# nrf7140_wificore register map
Vendor: Nordic Semiconductor; Series: nRF71; File version: 1
Registers are 32-bit, read-write, reset 0x0 unless marked. A register's access mark holds for its fields unless they carry their own. Offsets are from the block's base; [hi:lo] are bit positions; lines under a group give offsets from that group; {n}, {i} and the like mark numbered series; 'fields as' and 'values as' point back to an identical list.

## GLOBAL_MEMCONF310 — Memory configuration
Base 0x49011000
Same registers: MEMCONF 0x48013000
{0x500+0x10*i} POWER[{i}] (i=0..1) group — Unspecified
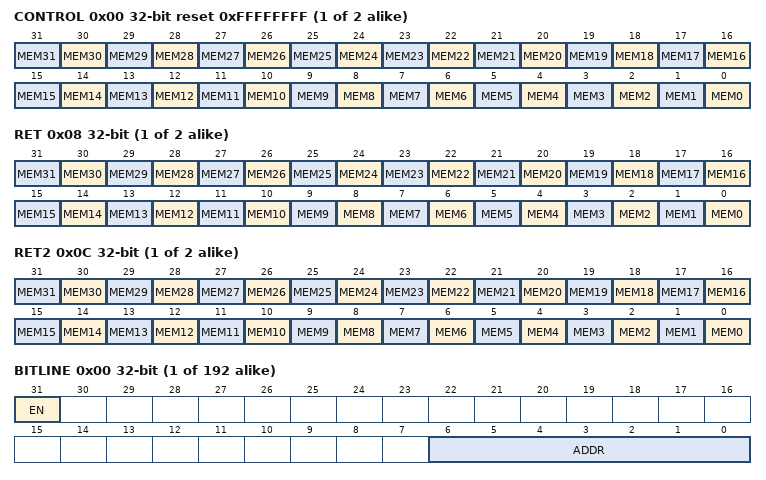
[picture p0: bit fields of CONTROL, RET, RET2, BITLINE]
  0x00 CONTROL reset 0xFFFFFFFF — Description cluster: Control memory block power.
    [all] fields
      0=Off (Power down); 1=On (Power up)
    [n] MEM{n} (n=0..31) — Keep the memory block MEM[{n}] on or off when in System ON mode.
  0x08 RET — Description cluster: RAM retention for RAM [n].
    [all] fields
      0=Off (Retention off); 1=On (Retention on)
    [n] MEM{n} (n=0..31) — Keep the RAM block MEM[{n}] retained when the parent power domain of the RAM is off.
  0x0C RET2 — Description cluster: RAM retention for the second bank in the RAM block
    [all] fields
      0=Off (Retention off); 1=On (Retention on)
    [n] MEM{n} (n=0..31) — Keep the second bank in RAM block MEM[{n}] retained when parent power domain of the RAM is off.
{0x600+4i} REPAIR[{i}] (i=0..191) group — Unspecified
  0x00 BITLINE — Description cluster: Repair configuration for RAM blocks.
    [31] EN — Enable bitline repair
      0=Disabled (Repair disabled.); 1=Enabled (Repair enabled.)
    [6:0] ADDR — Repair address of the bitline
{0x900+4i} BLOCKTYPE[{i}] (i=0..63) group — Unspecified
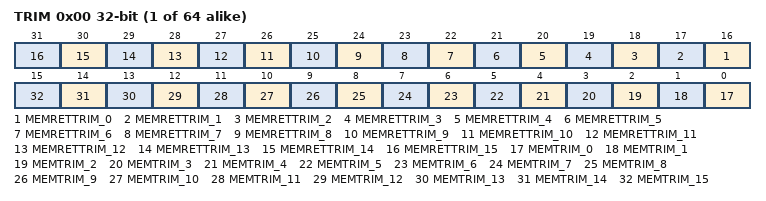
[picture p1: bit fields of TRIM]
  0x00 TRIM — Description cluster: Trim configuration for the memory block types.
    [n+16] MEMRETTRIM_{n} (n=0..15) — Trimming for retention mode for decreased leakage. Must be kept active in RAM retention mode.
    [n] MEMTRIM_{n} (n=0..15) — Read/write margin trim.

## BELLBOARD — BELLBOARD APB registers
Base 0x4F09C000
{0x0+4i} TASKS_TRIGGER[{i}] (i=0..31) wo — Description collection: Task TRIGGER[n]
  [0] TASKS_TRIGGER — Task TRIGGER[n]
    1=Trigger task
{0x100+4i} EVENTS_TRIGGERED[{i}] (i=0..31) — Description collection: Event TRIGGERED[n]
  [0] EVENTS_TRIGGERED — Event TRIGGERED[n]
    0=NotGenerated (Event not generated); 1=Generated (Event generated)
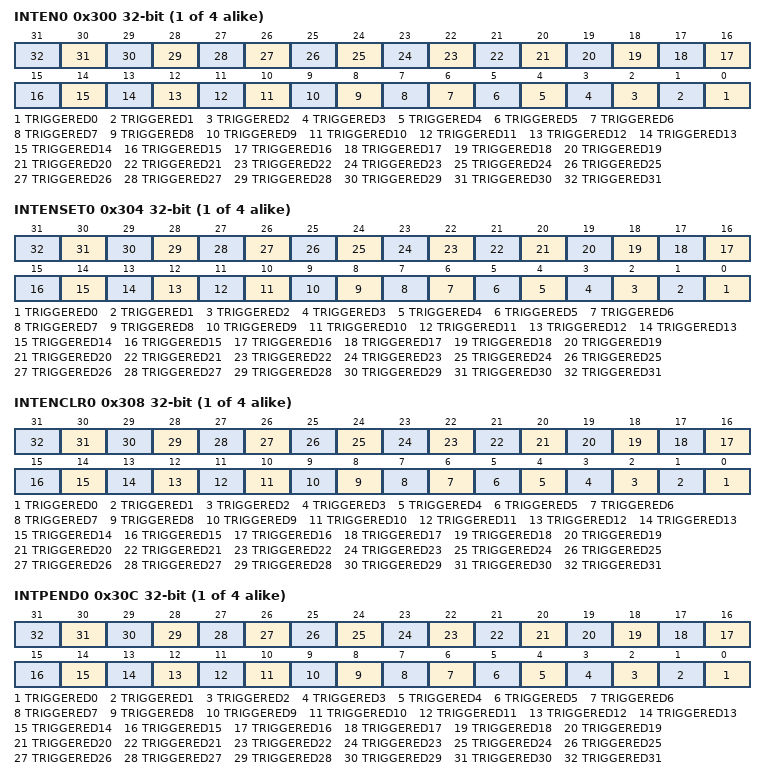
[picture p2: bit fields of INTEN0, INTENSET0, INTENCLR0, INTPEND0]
{0x300+0x10*i} INTEN{i} (i=0..3) — Enable or disable interrupt
  [all] fields
    0=Disabled; 1=Enabled
  [n] TRIGGERED{n} (n=0..31) — Enable or disable interrupt for event TRIGGERED[{n}]
{0x304+0x10*i} INTENSET{i} (i=0..3) — Enable interrupt
  [all] fields
    on read: 0=Disabled (Read: Disabled); 1=Enabled (Read: Enabled) | on write: 1=Set (Enable)
  [n] TRIGGERED{n} (n=0..31) — Write '1' to enable interrupt for event TRIGGERED[{n}]
{0x308+0x10*i} INTENCLR{i} (i=0..3) — Disable interrupt
  [all] fields
    on read: 0=Disabled (Read: Disabled); 1=Enabled (Read: Enabled) | on write: 1=Clear (Disable)
  [n] TRIGGERED{n} (n=0..31) — Write '1' to disable interrupt for event TRIGGERED[{n}]
{0x30C+0x10*i} INTPEND{i} ro (i=0..3) — Pending interrupts
  [all] fields
    on read: 0=NotPending (Read: Not pending); 1=Pending (Read: Pending)
  [n] TRIGGERED{n} (n=0..31) — Read pending status of interrupt for event TRIGGERED[{n}]

## GLOBAL_TBM — Trace buffer monitor
Base 0xBF003000
0x00 TASKS_START wo — Start counter
  [0] TASKS_START
    1=Trigger task
0x04 TASKS_STOP wo — Stop counter, clear counter value
  [0] TASKS_STOP
    1=Trigger task
0x08 TASKS_FLUSH wo — Save current counter value to COUNTSNAPSHOT
  [0] TASKS_FLUSH
    1=Trigger task
0x100 EVENTS_HALFFULL — Counter value equals half-full
  [0] EVENTS_HALFFULL
    0=NotGenerated (Event not generated); 1=Generated (Event generated)
0x104 EVENTS_FULL — Counter value equals full
  [0] EVENTS_FULL
    values as EVENTS_HALFFULL.EVENTS_HALFFULL
0x108 EVENTS_FLUSH — Counter value saved to COUNTSNAPSHOT due to flush
  [0] EVENTS_FLUSH
    values as EVENTS_HALFFULL.EVENTS_HALFFULL
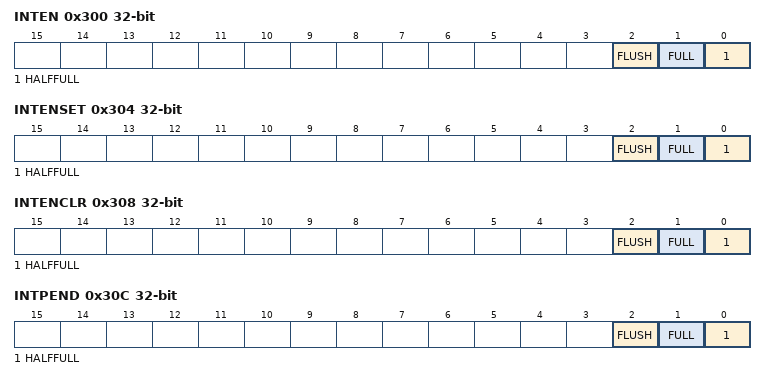
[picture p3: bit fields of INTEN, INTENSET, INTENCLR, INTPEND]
0x300 INTEN — Enable or disable interrupt
  [all] fields
    0=Disabled; 1=Enabled
  [2] FLUSH — Enable or disable interrupt for event FLUSH
  [1] FULL — Enable or disable interrupt for event FULL
  [0] HALFFULL — Enable or disable interrupt for event HALFFULL
0x304 INTENSET — Enable interrupt
  [all] fields
    on read: 0=Disabled (Read: Disabled); 1=Enabled (Read: Enabled) | on write: 1=Set (Enable)
  [2] FLUSH — Write '1' to enable interrupt for event FLUSH
  [1] FULL — Write '1' to enable interrupt for event FULL
  [0] HALFFULL — Write '1' to enable interrupt for event HALFFULL
0x308 INTENCLR — Disable interrupt
  [all] fields
    on read: 0=Disabled (Read: Disabled); 1=Enabled (Read: Enabled) | on write: 1=Clear (Disable)
  [2] FLUSH — Write '1' to disable interrupt for event FLUSH
  [1] FULL — Write '1' to disable interrupt for event FULL
  [0] HALFFULL — Write '1' to disable interrupt for event HALFFULL
0x30C INTPEND ro — Pending interrupts
  [all] fields
    on read: 0=NotPending (Read: Not pending); 1=Pending (Read: Pending)
  [2] FLUSH — Read pending status of interrupt for event FLUSH
  [1] FULL — Read pending status of interrupt for event FULL
  [0] HALFFULL — Read pending status of interrupt for event HALFFULL
0x400 BUFFERSIZE reset 0x400 — System RAM trace buffer total size in bytes
  [12:0] BUFFERSIZE — Must only be configured in STOP mode. Must be programmed to multiple of 16 bytes to make half-buffer size always 64 bit word aligned. Typical minimum BUFFERSIZE value 0x010 i.e. 16 bytes, typical maximum value 0x1000 i.e. 4096 bytes.
    0=Zero (0 bytes); 16=Min (16 bytes); 0x1000=Max (4096 bytes)
0x404 COUNT — Counter current value
  [12:0] COUNT — Counter current value. Only writable when counter is in stopped state. Writing when not in stopped state will generate a bus fault.
0x408 COUNTSNAPSHOT ro — Copy of the current COUNT value
  [12:0] COUNTSNAPSHOT — TASKS_FLUSH will copy the current COUNT value to this register.
